AUTOSAR XML (schema 4-3-0)
package /ComponentTypes
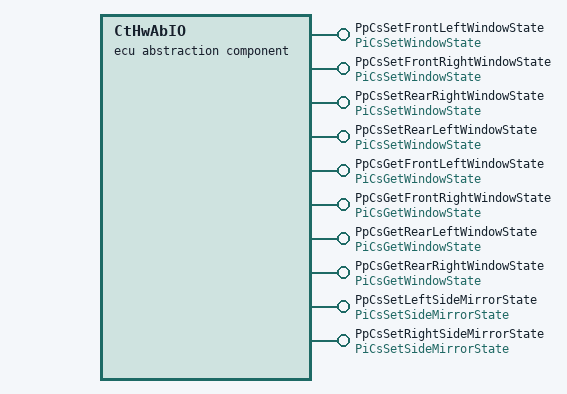
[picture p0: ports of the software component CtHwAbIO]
  ecu abstraction sw component type CtHwAbIO
    10 x provide port:
      PpCsSetFrontLeftWindowState: provided-com-specs=[{operation=Operation, queue-length=1}, {operation=WriteToWindow, queue-length=1}], provided-interface=PiCsSetWindowState
      PpCsSetFrontRightWindowState: provided-com-specs=[{operation=Operation, queue-length=1}, {operation=WriteToWindow, queue-length=1}], provided-interface=PiCsSetWindowState
      PpCsSetRearRightWindowState: provided-com-specs=[{operation=Operation, queue-length=1}, {operation=WriteToWindow, queue-length=1}], provided-interface=PiCsSetWindowState
      PpCsSetRearLeftWindowState: provided-com-specs=[{operation=Operation, queue-length=1}, {operation=WriteToWindow, queue-length=1}], provided-interface=PiCsSetWindowState
      PpCsGetFrontLeftWindowState: provided-com-specs=[{operation=Operation, queue-length=1}, {operation=ReadFromWindowState, queue-length=1}], provided-interface=PiCsGetWindowState
      PpCsGetFrontRightWindowState: provided-com-specs=[{operation=Operation, queue-length=1}, {operation=ReadFromWindowState, queue-length=1}], provided-interface=PiCsGetWindowState
      PpCsGetRearLeftWindowState: provided-com-specs=[{operation=Operation, queue-length=1}, {operation=ReadFromWindowState, queue-length=1}], provided-interface=PiCsGetWindowState
      PpCsGetRearRightWindowState: provided-com-specs=[{operation=Operation, queue-length=1}, {operation=ReadFromWindowState, queue-length=1}], provided-interface=PiCsGetWindowState
      PpCsSetLeftSideMirrorState: provided-com-specs=[{operation=Operation, queue-length=1}, {operation=WriteToSideMirror, queue-length=1}], provided-interface=PiCsSetSideMirrorState
      PpCsSetRightSideMirrorState: provided-com-specs=[{operation=Operation, queue-length=1}, {operation=WriteToSideMirror, queue-length=1}], provided-interface=PiCsSetSideMirrorState
    behavior CtHwAbIO_InternalBehavior
      4 x operation invoked event:
        OIT_HwAbFrontLeftState_ReadChannel_PpCsGetFrontLeftWindowState_ReadFromWindowState: start-on-event=HwAbFrontLeftState_ReadChannel, operation=PpCsGetFrontLeftWindowState.ReadFromWindowState
        OIT_HwAbFrontRightState_ReadChannel_PpCsGetFrontRightWindowState_ReadFromWindowState: start-on-event=HwAbFrontRightState_ReadChannel, operation=PpCsGetFrontRightWindowState.ReadFromWindowState
        OIT_HwAbRearLeftState_ReadChannel_PpCsGetRearLeftWindowState_ReadFromWindowState: start-on-event=HwAbRearLeftState_ReadChannel, operation=PpCsGetRearLeftWindowState.ReadFromWindowState
        OIT_HwAbRearRightState_ReadChannel_PpCsGetRearRightWindowState_ReadFromWindowState: start-on-event=HwAbRearRightState_ReadChannel, operation=PpCsGetRearRightWindowState.ReadFromWindowState
      4 x runnable:
        HwAbFrontLeftState_ReadChannel
        HwAbFrontRightState_ReadChannel
        HwAbRearLeftState_ReadChannel
        HwAbRearRightState_ReadChannel
  swc implementation CtHwAbIO_Implementation: behavior=CtHwAbIO_InternalBehavior
